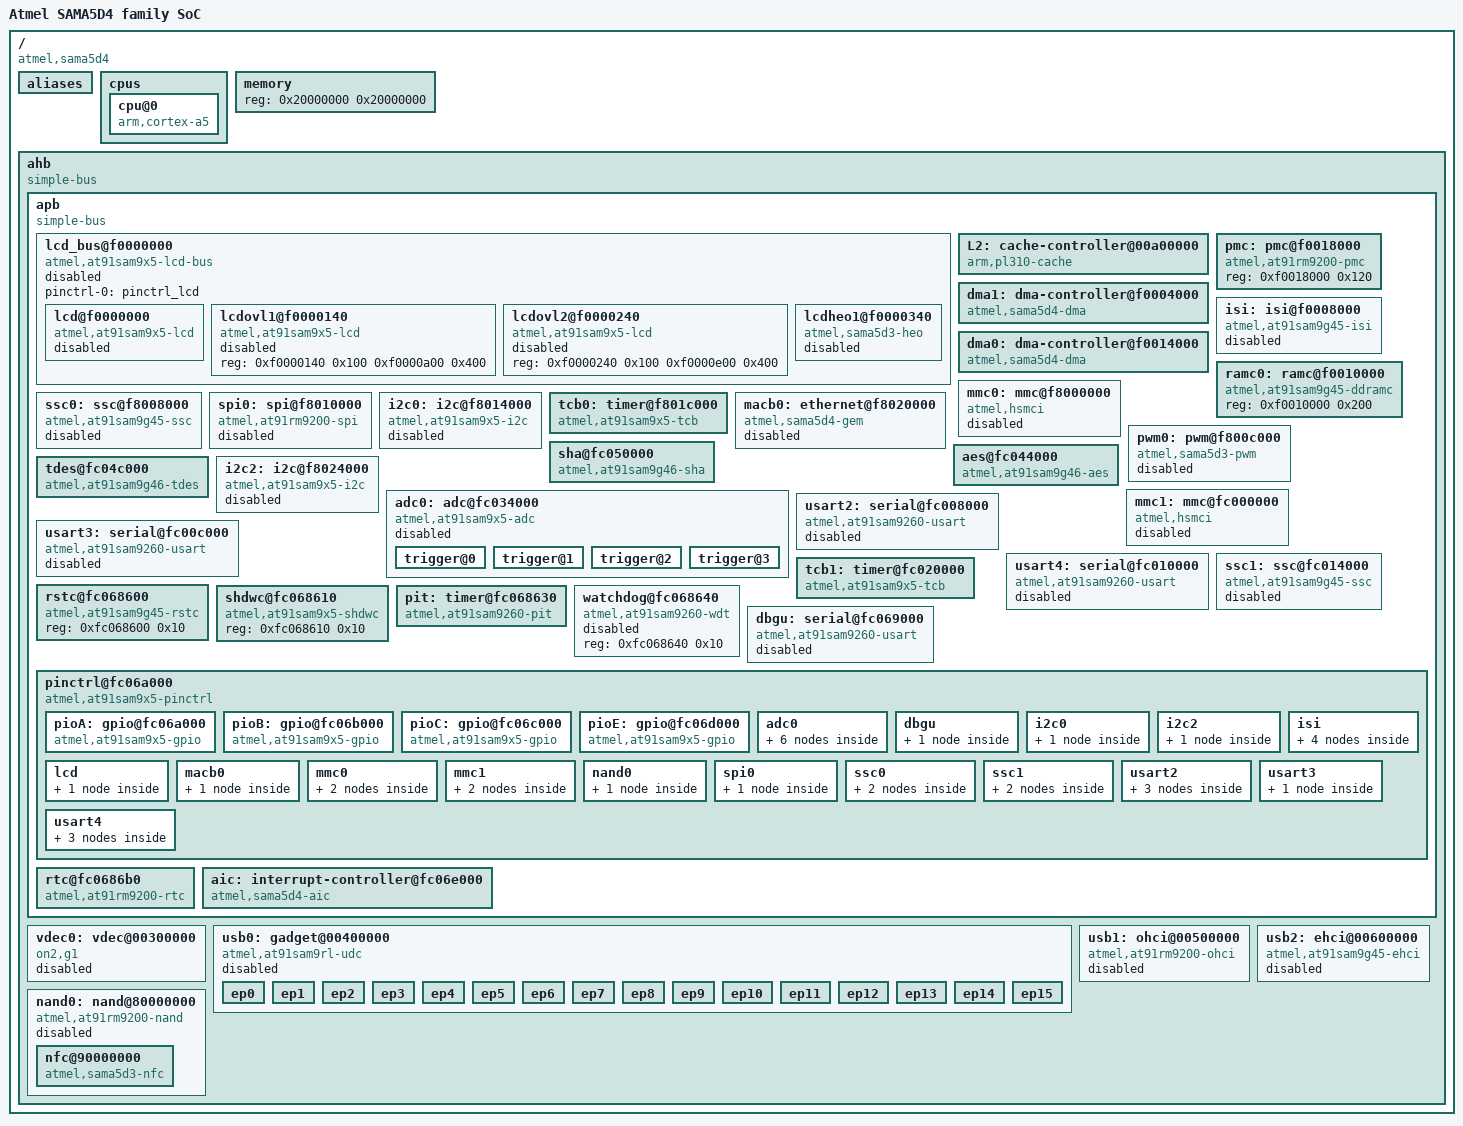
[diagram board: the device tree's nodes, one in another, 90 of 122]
/*
 * sama5d4.dtsi - Device Tree Include file for SAMA5D4 family SoC
 *
 *  Copyright (C) 2013 Atmel,
 *                2013 Nicolas Ferre <nicolas.ferre@atmel.com>
 *
 * Licensed under GPLv2 or later.
 */

#include "skeleton.dtsi"
#include <dt-bindings/dma/at91.h>
#include <dt-bindings/pinctrl/at91.h>
#include <dt-bindings/interrupt-controller/irq.h>
#include <dt-bindings/gpio/gpio.h>

/ {
	model = "Atmel SAMA5D4 family SoC";
	compatible = "atmel,sama5d4";
	interrupt-parent = <&aic>;

	aliases {
		serial0 = &usart3;
		serial1 = &usart4;
		serial2 = &usart2;
		gpio0 = &pioA;
		gpio1 = &pioB;
		gpio2 = &pioC;
		gpio4 = &pioE;
		tcb0 = &tcb0;
		tcb1 = &tcb1;
		i2c2 = &i2c2;
		ssc0 = &ssc0;
		ssc1 = &ssc1;
		pwm0 = &pwm0;
	};
	cpus {
		#address-cells = <1>;
		#size-cells = <0>;

		cpu@0 {
			device_type = "cpu";
			compatible = "arm,cortex-a5";
			reg = <0>;
			next-level-cache = <&L2>;
		};
	};

	memory {
		reg = <0x20000000 0x20000000>;
	};

	ahb {
		compatible = "simple-bus";
		#address-cells = <1>;
		#size-cells = <1>;
		ranges;

		apb {
			compatible = "simple-bus";
			#address-cells = <1>;
			#size-cells = <1>;
			ranges;

			lcd_bus@f0000000 {
				#address-cells = <1>;
				#size-cells = <1>;
				compatible = "atmel,at91sam9x5-lcd-bus", "simple-bus";
				ranges = <0xf0000000 0xf0000000 0x2000>;
				pinctrl-names = "default";
				pinctrl-0 = <&pinctrl_lcd>;
				status = "disabled";

				lcd@f0000000 {
					compatible = "atmel,at91sam9x5-lcd";
					reg = <0xf0000000 0x100
					       0xf0000600 0x400>;
					interrupts = <51 IRQ_TYPE_LEVEL_HIGH 3>;
					status = "disabled";
				};

				lcdovl1@f0000140 {
					compatible = "atmel,at91sam9x5-lcd";
					reg = <0xf0000140 0x100
					       0xf0000a00 0x400>;
					status = "disabled";
				};

				lcdovl2@f0000240 {
					compatible = "atmel,at91sam9x5-lcd";
					reg = <0xf0000240 0x100
					       0xf0000e00 0x400>;
					status = "disabled";
				};

				lcdheo1@f0000340 {
					compatible = "atmel,sama5d3-heo";
					reg = <0xf0000340 0x100
					       0xf0001200 0x400>;
					interrupts = <51 IRQ_TYPE_LEVEL_HIGH 3>;
					status = "disabled";
				};
			};

			L2: cache-controller@00a00000 {
				compatible = "arm,pl310-cache";
				reg = <0x00a00000 0x1000>;
				interrupts = <67 IRQ_TYPE_LEVEL_HIGH 0>;
				cache-unified;
				cache-level = <2>;
				/*arm,data-latency = <1 1 1>;*/
				/*arm,tag-latency = <1 1 1>;*/
			};

			pmc: pmc@f0018000 {
				compatible = "atmel,at91rm9200-pmc";
				reg = <0xf0018000 0x120>;
			};

			dma1: dma-controller@f0004000 {
				compatible = "atmel,sama5d4-dma";
				reg = <0xf0004000 0x200>;
				interrupts = <50 IRQ_TYPE_LEVEL_HIGH 0>;
				#dma-cells = <2>;
			};

			dma0: dma-controller@f0014000 {
				compatible = "atmel,sama5d4-dma";
				reg = <0xf0014000 0x200>;
				interrupts = <8 IRQ_TYPE_LEVEL_HIGH 0>;
				#dma-cells = <2>;
			};

			isi: isi@f0008000 {
				compatible = "atmel,at91sam9g45-isi";
				reg = <0xf0008000 0x4000>;
				interrupts = <52 IRQ_TYPE_LEVEL_HIGH 5>;
				pinctrl-names = "default";
				pinctrl-0 = <&pinctrl_isi &pinctrl_isi_mck &pinctrl_isi_power &pinctrl_isi_reset>;
				status = "disabled";
			};

			ramc0: ramc@f0010000 {
				compatible = "atmel,at91sam9g45-ddramc";
				reg = <0xf0010000 0x200>;
			};

			mmc0: mmc@f8000000 {
				compatible = "atmel,hsmci";
				reg = <0xf8000000 0x600>;
				interrupts = <35 IRQ_TYPE_LEVEL_HIGH 0>;
				dmas = <&dma1
					(AT91_XDMAC_DT_MEM_IF(0) | AT91_XDMAC_DT_PER_IF(1))
					(AT91_XDMAC_DT_PERID(0) | AT91_XDMAC_DT_DWIDTH(0x2))>;
				dma-names = "rxtx";
				pinctrl-names = "default";
				pinctrl-0 = <&pinctrl_mmc0_clk_cmd_dat0 &pinctrl_mmc0_dat1_3>;
				status = "disabled";
				#address-cells = <1>;
				#size-cells = <0>;
			};

			ssc0: ssc@f8008000 {
				compatible = "atmel,at91sam9g45-ssc";
				reg = <0xf8008000 0x4000>;
				interrupts = <48 IRQ_TYPE_LEVEL_HIGH 0>;
				pinctrl-names = "default";
				pinctrl-0 = <&pinctrl_ssc0_tx &pinctrl_ssc0_rx>;
				dmas = <&dma1
					(AT91_XDMAC_DT_MEM_IF(0) | AT91_XDMAC_DT_PER_IF(1))
					(AT91_XDMAC_DT_PERID(26) | AT91_XDMAC_DT_DWIDTH(0x1))>,
				       <&dma1
					(AT91_XDMAC_DT_MEM_IF(0) | AT91_XDMAC_DT_PER_IF(1))
					(AT91_XDMAC_DT_PERID(27) | AT91_XDMAC_DT_DWIDTH(0x1))>;
				dma-names = "tx", "rx";
				status = "disabled";
			};


			spi0: spi@f8010000 {
				#address-cells = <1>;
				#size-cells = <0>;
				compatible = "atmel,at91rm9200-spi";
				reg = <0xf8010000 0x100>;
				interrupts = <37 IRQ_TYPE_LEVEL_HIGH 3>;
				dmas = <&dma1
					(AT91_XDMAC_DT_MEM_IF(0) | AT91_XDMAC_DT_PER_IF(1))
					AT91_XDMAC_DT_PERID(10)>,
				       <&dma1
					(AT91_XDMAC_DT_MEM_IF(0) | AT91_XDMAC_DT_PER_IF(1))
					AT91_XDMAC_DT_PERID(11)>;
				dma-names = "tx", "rx";
				pinctrl-names = "default";
				pinctrl-0 = <&pinctrl_spi0>;
				status = "disabled";
			};

			i2c0: i2c@f8014000 {
				compatible = "atmel,at91sam9x5-i2c";
				reg = <0xf8014000 0x4000>;
				interrupts = <32 IRQ_TYPE_LEVEL_HIGH 6>;
				dmas = <&dma1
					(AT91_XDMAC_DT_MEM_IF(0) | AT91_XDMAC_DT_PER_IF(1))
					AT91_XDMAC_DT_PERID(2)>,
				       <&dma1
					(AT91_XDMAC_DT_MEM_IF(0) | AT91_XDMAC_DT_PER_IF(1))
					AT91_XDMAC_DT_PERID(3)>;
				dma-names = "tx", "rx";
				pinctrl-names = "default";
				pinctrl-0 = <&pinctrl_i2c0>;
				#address-cells = <1>;
				#size-cells = <0>;
				status = "disabled";
			};

			tcb0: timer@f801c000 {
				compatible = "atmel,at91sam9x5-tcb";
				reg = <0xf801c000 0x100>;
				interrupts = <40 IRQ_TYPE_LEVEL_HIGH 0>;
			};

			macb0: ethernet@f8020000 {
				compatible = "atmel,sama5d4-gem";
				reg = <0xf8020000 0x100>;
				interrupts = <54 IRQ_TYPE_LEVEL_HIGH 3>;
				pinctrl-names = "default";
				pinctrl-0 = <&pinctrl_macb0_rmii>;
				status = "disabled";
			};

			pwm0: pwm@f800c000 {
				compatible = "atmel,sama5d3-pwm";
				reg = <0xf800c000 0x300>;
				interrupts = <43 IRQ_TYPE_LEVEL_HIGH 4>;
				#pwm-cells = <3>;
				status = "disabled";
			};

			sha@fc050000 {
				compatible = "atmel,at91sam9g46-sha";
				reg = <0xfc050000 0x100>;
				interrupts = <15 IRQ_TYPE_LEVEL_HIGH 0>;
				dmas = <&dma0 (AT91_XDMAC_DT_MEM_IF(0) | AT91_XDMAC_DT_PER_IF(1))
					AT91_XDMAC_DT_PERID(44)>;
				dma-names = "tx";
			};

			aes@fc044000 {
				compatible = "atmel,at91sam9g46-aes";
				reg = <0xfc044000 0x100>;
				interrupts = <12 IRQ_TYPE_LEVEL_HIGH 0>;
				dmas = <&dma0 (AT91_XDMAC_DT_MEM_IF(0) | AT91_XDMAC_DT_PER_IF(1))
					AT91_XDMAC_DT_PERID(41)>,
					<&dma0 (AT91_XDMAC_DT_MEM_IF(0) | AT91_XDMAC_DT_PER_IF(1))
					AT91_XDMAC_DT_PERID(40)>;
				dma-names = "tx", "rx";
			};

			tdes@fc04c000 {
				compatible = "atmel,at91sam9g46-tdes";
				reg = <0xfc04c000 0x100>;
				interrupts = <14 IRQ_TYPE_LEVEL_HIGH 0>;
				dmas = <&dma0 (AT91_XDMAC_DT_MEM_IF(0) | AT91_XDMAC_DT_PER_IF(1))
					AT91_XDMAC_DT_PERID(42)>,
					<&dma0 (AT91_XDMAC_DT_MEM_IF(0) | AT91_XDMAC_DT_PER_IF(1))
					AT91_XDMAC_DT_PERID(43)>;
				dma-names = "tx", "rx";
			};

			i2c2: i2c@f8024000 {
				compatible = "atmel,at91sam9x5-i2c";
				reg = <0xf8024000 0x4000>;
				interrupts = <34 4 6>;
				dmas = <&dma1
					(AT91_XDMAC_DT_MEM_IF(0) | AT91_XDMAC_DT_PER_IF(1))
					AT91_XDMAC_DT_PERID(6)>,
				       <&dma1
					(AT91_XDMAC_DT_MEM_IF(0) | AT91_XDMAC_DT_PER_IF(1))
					AT91_XDMAC_DT_PERID(7)>;
				dma-names = "tx", "rx";
				pinctrl-names = "default";
				pinctrl-0 = <&pinctrl_i2c2>;
				#address-cells = <1>;
				#size-cells = <0>;
				status = "disabled";
			};

			adc0: adc@fc034000 {
				compatible = "atmel,at91sam9x5-adc";
				reg = <0xfc034000 0x100>;
				interrupts = <44 IRQ_TYPE_LEVEL_HIGH 5>;
				pinctrl-names = "default";
				pinctrl-0 = <
					/* external trigger is conflict with USBA_VBUS */
					&pinctrl_adc0_ad0
					&pinctrl_adc0_ad1
					&pinctrl_adc0_ad2
					&pinctrl_adc0_ad3
					&pinctrl_adc0_ad4
					>;
				atmel,adc-channels-used = <0x01f>;
				atmel,adc-startup-time = <40>;
				atmel,adc-use-external;
				atmel,adc-vref = <3000>;
				atmel,adc-res = <8 10>;
				atmel,adc-sample-hold-time = <11>;
				atmel,adc-res-names = "lowres", "highres";
				atmel,adc-clock-rate = <1000000>;
				atmel,adc-ts-pressure-threshold = <10000>;
				status = "disabled";

				trigger@0 {
					trigger-name = "external-rising";
					trigger-value = <0x1>;
					trigger-external;
				};
				trigger@1 {
					trigger-name = "external-falling";
					trigger-value = <0x2>;
					trigger-external;
				};
				trigger@2 {
					trigger-name = "external-any";
					trigger-value = <0x3>;
					trigger-external;
				};
				trigger@3 {
					trigger-name = "continuous";
					trigger-value = <0x6>;
				};
			};

			mmc1: mmc@fc000000 {
				compatible = "atmel,hsmci";
				reg = <0xfc000000 0x600>;
				interrupts = <36 IRQ_TYPE_LEVEL_HIGH 0>;
				dmas = <&dma1
					(AT91_XDMAC_DT_MEM_IF(0) | AT91_XDMAC_DT_PER_IF(1))
					(AT91_XDMAC_DT_PERID(1) | AT91_XDMAC_DT_DWIDTH(0x2))>;
				dma-names = "rxtx";
				pinctrl-names = "default";
				pinctrl-0 = <&pinctrl_mmc1_clk_cmd_dat0 &pinctrl_mmc1_dat1_3>;
				status = "disabled";
				#address-cells = <1>;
				#size-cells = <0>;
			};

			usart2: serial@fc008000 {
				compatible = "atmel,at91sam9260-usart";
				reg = <0xfc008000 0x100>;
				interrupts = <29 IRQ_TYPE_LEVEL_HIGH 5>;
				dmas = <&dma1
					(AT91_XDMAC_DT_MEM_IF(0) | AT91_XDMAC_DT_PER_IF(1))
					(AT91_XDMAC_DT_PERID(16) | AT91_XDMAC_DT_DWIDTH(0x0))>,
				       <&dma1
					(AT91_XDMAC_DT_MEM_IF(0) | AT91_XDMAC_DT_PER_IF(1))
					(AT91_XDMAC_DT_PERID(17) | AT91_XDMAC_DT_DWIDTH(0x0))>;
				dma-names = "tx", "rx";
				pinctrl-names = "default";
				pinctrl-0 = <&pinctrl_usart2 &pinctrl_usart2_rts &pinctrl_usart2_cts>;
				status = "disabled";
			};

			usart3: serial@fc00c000 {
				compatible = "atmel,at91sam9260-usart";
				reg = <0xfc00c000 0x100>;
				interrupts = <30 IRQ_TYPE_LEVEL_HIGH 5>;
				dmas = <&dma1
					(AT91_XDMAC_DT_MEM_IF(0) | AT91_XDMAC_DT_PER_IF(1))
					(AT91_XDMAC_DT_PERID(18) | AT91_XDMAC_DT_DWIDTH(0x0))>,
				       <&dma1
					(AT91_XDMAC_DT_MEM_IF(0) | AT91_XDMAC_DT_PER_IF(1))
					(AT91_XDMAC_DT_PERID(19) | AT91_XDMAC_DT_DWIDTH(0x0))>;
				dma-names = "tx", "rx";
				pinctrl-names = "default";
				pinctrl-0 = <&pinctrl_usart3>;
				status = "disabled";
			};

			usart4: serial@fc010000 {
				compatible = "atmel,at91sam9260-usart";
				reg = <0xfc010000 0x100>;
				interrupts = <31 IRQ_TYPE_LEVEL_HIGH 5>;
				dmas = <&dma1
					(AT91_XDMAC_DT_MEM_IF(0) | AT91_XDMAC_DT_PER_IF(1))
					(AT91_XDMAC_DT_PERID(20) | AT91_XDMAC_DT_DWIDTH(0x0))>,
				       <&dma1
					(AT91_XDMAC_DT_MEM_IF(0) | AT91_XDMAC_DT_PER_IF(1))
					(AT91_XDMAC_DT_PERID(21) | AT91_XDMAC_DT_DWIDTH(0x0))>;
				dma-names = "tx", "rx";
				pinctrl-names = "default";
				pinctrl-0 = <&pinctrl_usart4>;
				status = "disabled";
			};

			ssc1: ssc@fc014000 {
				compatible = "atmel,at91sam9g45-ssc";
				reg = <0xfc014000 0x4000>;
				interrupts = <49 IRQ_TYPE_LEVEL_HIGH 0>;
				pinctrl-names = "default";
				pinctrl-0 = <&pinctrl_ssc1_tx &pinctrl_ssc1_rx>;
				dmas = <&dma1 AT91_XDMAC_DT_PERID(28)>,
				       <&dma1 AT91_XDMAC_DT_PERID(29)>;
				dma-names = "tx", "rx";
				status = "disabled";
			};

			tcb1: timer@fc020000 {
				compatible = "atmel,at91sam9x5-tcb";
				reg = <0xfc020000 0x100>;
				interrupts = <41 IRQ_TYPE_LEVEL_HIGH 0>;
			};

			rstc@fc068600 {
				compatible = "atmel,at91sam9g45-rstc";
				reg = <0xfc068600 0x10>;
			};

			shdwc@fc068610 {
				compatible = "atmel,at91sam9x5-shdwc";
				reg = <0xfc068610 0x10>;
			};

			pit: timer@fc068630 {
				compatible = "atmel,at91sam9260-pit";
				reg = <0xfc068630 0xf>;
				interrupts = <3 IRQ_TYPE_LEVEL_HIGH 5>;
			};

			watchdog@fc068640 {
				compatible = "atmel,at91sam9260-wdt";
				reg = <0xfc068640 0x10>;
				status = "disabled";
			};

			dbgu: serial@fc069000 {
				compatible = "atmel,at91sam9260-usart";
				reg = <0xfc069000 0x200>;
				interrupts = <2 IRQ_TYPE_LEVEL_HIGH 7>;
				pinctrl-names = "default";
				pinctrl-0 = <&pinctrl_dbgu>;
				status = "disabled";
			};


			pinctrl@fc06a000 {
				#address-cells = <1>;
				#size-cells = <1>;
				compatible = "atmel,at91sam9x5-pinctrl", "atmel,at91rm9200-pinctrl", "simple-bus";
				ranges = <0xfc06a000 0xfc06a000 0x4000>;
				/* WARNING: revisit as pin spec has changed */
				atmel,mux-mask = <
					/*   A          B          C  */
					0xffffffff 0x3ffcfe7c 0x1c010101	/* pioA */
					0x7fffffff 0xfffccc3a 0x3f00cc3a	/* pioB */
					0xffffffff 0x3ff83fff 0xff00ffff	/* pioC */
					0x00000000 0x00000000 0x00000000	/* pioD */
					0xffffffff 0x7fffffff 0x76fff1bf	/* pioE */
					>;

				pioA: gpio@fc06a000 {
					compatible = "atmel,at91sam9x5-gpio", "atmel,at91rm9200-gpio";
					reg = <0xfc06a000 0x100>;
					interrupts = <23 IRQ_TYPE_LEVEL_HIGH 1>;
					#gpio-cells = <2>;
					gpio-controller;
					interrupt-controller;
					#interrupt-cells = <2>;
				};

				pioB: gpio@fc06b000 {
					compatible = "atmel,at91sam9x5-gpio", "atmel,at91rm9200-gpio";
					reg = <0xfc06b000 0x100>;
					interrupts = <24 IRQ_TYPE_LEVEL_HIGH 1>;
					#gpio-cells = <2>;
					gpio-controller;
					interrupt-controller;
					#interrupt-cells = <2>;
				};

				pioC: gpio@fc06c000 {
					compatible = "atmel,at91sam9x5-gpio", "atmel,at91rm9200-gpio";
					reg = <0xfc06c000 0x100>;
					interrupts = <25 IRQ_TYPE_LEVEL_HIGH 1>;
					#gpio-cells = <2>;
					gpio-controller;
					interrupt-controller;
					#interrupt-cells = <2>;
				};

				pioE: gpio@fc06d000 {
					compatible = "atmel,at91sam9x5-gpio", "atmel,at91rm9200-gpio";
					reg = <0xfc06d000 0x100>;
					interrupts = <26 IRQ_TYPE_LEVEL_HIGH 1>;
					#gpio-cells = <2>;
					gpio-controller;
					interrupt-controller;
					#interrupt-cells = <2>;
				};

				/* pinctrl pin settings */
				adc0 {
					pinctrl_adc0_adtrg: adc0_adtrg {
						atmel,pins =
							<AT91_PIOE 31 AT91_PERIPH_A AT91_PINCTRL_NONE>;	/* conflicts with USBA_VBUS */
					};
					pinctrl_adc0_ad0: adc0_ad0 {
						atmel,pins =
							<AT91_PIOC 27 AT91_PERIPH_A AT91_PINCTRL_NONE>;
					};
					pinctrl_adc0_ad1: adc0_ad1 {
						atmel,pins =
							<AT91_PIOC 28 AT91_PERIPH_A AT91_PINCTRL_NONE>;
					};
					pinctrl_adc0_ad2: adc0_ad2 {
						atmel,pins =
							<AT91_PIOC 29 AT91_PERIPH_A AT91_PINCTRL_NONE>;
					};
					pinctrl_adc0_ad3: adc0_ad3 {
						atmel,pins =
							<AT91_PIOC 30 AT91_PERIPH_A AT91_PINCTRL_NONE>;
					};
					pinctrl_adc0_ad4: adc0_ad4 {
						atmel,pins =
							<AT91_PIOC 31 AT91_PERIPH_A AT91_PINCTRL_NONE>;
					};
				};

				dbgu {
					pinctrl_dbgu: dbgu-0 {
						atmel,pins =
							<AT91_PIOB 24 AT91_PERIPH_A AT91_PINCTRL_NONE>,     /* conflicts with D14 and TDI */
							<AT91_PIOB 25 AT91_PERIPH_A AT91_PINCTRL_PULL_UP>;  /* conflicts with D15 and TDO */
					};
				};

				i2c0 {
					pinctrl_i2c0: i2c0-0 {
						atmel,pins =
							<AT91_PIOA 30 AT91_PERIPH_A AT91_PINCTRL_NONE
							 AT91_PIOA 31 AT91_PERIPH_A AT91_PINCTRL_NONE>;
					};
				};

				i2c2 {
					pinctrl_i2c2: i2c2-0 {
						atmel,pins =
							<AT91_PIOB 29 AT91_PERIPH_A AT91_PINCTRL_NONE	/* TWD2, conflicts with RD0 and PWML1 */
							 AT91_PIOB 30 AT91_PERIPH_A AT91_PINCTRL_NONE>; /* TWCK2, conflicts with RF0 */
					};
				};

				isi {
					pinctrl_isi: isi-0 {
						atmel,pins =
							<AT91_PIOC 19 AT91_PERIPH_A AT91_PINCTRL_NONE	/* ISI_D0 */
							 AT91_PIOC 20 AT91_PERIPH_A AT91_PINCTRL_NONE	/* ISI_D1 */
							 AT91_PIOC 21 AT91_PERIPH_A AT91_PINCTRL_NONE	/* ISI_D2 */
							 AT91_PIOC 22 AT91_PERIPH_A AT91_PINCTRL_NONE	/* ISI_D3 */
							 AT91_PIOC 23 AT91_PERIPH_A AT91_PINCTRL_NONE	/* ISI_D4 */
							 AT91_PIOC 24 AT91_PERIPH_A AT91_PINCTRL_NONE	/* ISI_D5 */
							 AT91_PIOC 25 AT91_PERIPH_A AT91_PINCTRL_NONE	/* ISI_D6 */
							 AT91_PIOC 26 AT91_PERIPH_A AT91_PINCTRL_NONE	/* ISI_D7 */
							 AT91_PIOB  1 AT91_PERIPH_C AT91_PINCTRL_NONE	/* ISI_PCK, conflict with G0_RXCK */
							 AT91_PIOB  3 AT91_PERIPH_C AT91_PINCTRL_NONE	/* ISI_VSYNC */
							 AT91_PIOB  4 AT91_PERIPH_C AT91_PINCTRL_NONE>;	/* ISI_HSYNC */
					};
					pinctrl_isi_mck: isi_mck-0 {
						atmel,pins =
							<AT91_PIOC 4 AT91_PERIPH_C AT91_PINCTRL_NONE>;	/* ISI_MCK(PCK1), conflict with MCI0_CK, SPI0_NPCS1 */
					};
					pinctrl_isi_reset: isi_reset-0 {
						atmel,pins =
							<AT91_PIOB 11 AT91_PERIPH_GPIO AT91_PINCTRL_NONE>;   /* PB11 gpio ISI_RST */
					};

					pinctrl_isi_power: isi_power-0 {
						atmel,pins =
							<AT91_PIOB 5 AT91_PERIPH_GPIO AT91_PINCTRL_NONE>; /* PB5 gpio ISI_PWD */
					};
				};

				lcd {
					pinctrl_lcd: lcd-0 {
						atmel,pins = <
							/* AT91_PIOA 0 AT91_PERIPH_A AT91_PINCTRL_NONE */ /* LCDDAT0, conflicts with TMS */
							 AT91_PIOA 1 AT91_PERIPH_A AT91_PINCTRL_NONE /* LCDDAT1 */
							 AT91_PIOA 2 AT91_PERIPH_A AT91_PINCTRL_NONE /* LCDDAT2 */
							 AT91_PIOA 3 AT91_PERIPH_A AT91_PINCTRL_NONE /* LCDDAT3 */
							 AT91_PIOA 4 AT91_PERIPH_A AT91_PINCTRL_NONE /* LCDDAT4 */
							 AT91_PIOA 5 AT91_PERIPH_A AT91_PINCTRL_NONE /* LCDDAT5 */
							 AT91_PIOA 6 AT91_PERIPH_A AT91_PINCTRL_NONE /* LCDDAT6 */
							 AT91_PIOA 7 AT91_PERIPH_A AT91_PINCTRL_NONE /* LCDDAT7 */
							/* AT91_PIOA 8 AT91_PERIPH_A AT91_PINCTRL_NONE */ /* LCDDAT8, conflicts with TCK */
							 AT91_PIOA 9 AT91_PERIPH_A AT91_PINCTRL_NONE /* LCDDAT9 */
							 AT91_PIOA 10 AT91_PERIPH_A AT91_PINCTRL_NONE /* LCDDAT10 */
							 AT91_PIOA 11 AT91_PERIPH_A AT91_PINCTRL_NONE /* LCDDAT11 */
							 AT91_PIOA 12 AT91_PERIPH_A AT91_PINCTRL_NONE /* LCDDAT12 */
							 AT91_PIOA 13 AT91_PERIPH_A AT91_PINCTRL_NONE /* LCDDAT13 */
							 AT91_PIOA 14 AT91_PERIPH_A AT91_PINCTRL_NONE /* LCDDAT14 */
							 AT91_PIOA 15 AT91_PERIPH_A AT91_PINCTRL_NONE /* LCDDAT15 */
							/* AT91_PIOA 16 AT91_PERIPH_A AT91_PINCTRL_NONE */ /* LCDDAT16, conflicts with NTRST */
							 AT91_PIOA 17 AT91_PERIPH_A AT91_PINCTRL_NONE /* LCDDAT17 */
							 AT91_PIOA 18 AT91_PERIPH_A AT91_PINCTRL_NONE /* LCDDAT18 */
							 AT91_PIOA 19 AT91_PERIPH_A AT91_PINCTRL_NONE /* LCDDAT19 */
							 AT91_PIOA 20 AT91_PERIPH_A AT91_PINCTRL_NONE /* LCDDAT20 */
							 AT91_PIOA 21 AT91_PERIPH_A AT91_PINCTRL_NONE /* LCDDAT21 */
							 AT91_PIOA 22 AT91_PERIPH_A AT91_PINCTRL_NONE /* LCDDAT22 */
							 AT91_PIOA 23 AT91_PERIPH_A AT91_PINCTRL_NONE /* LCDDAT23 */
							 AT91_PIOA 29 AT91_PERIPH_A AT91_PINCTRL_NONE /* LCDDEN, conflicts with PWML1 */
							 AT91_PIOA 27 AT91_PERIPH_A AT91_PINCTRL_NONE /* LCDHSYNC, conflicts with PWML0 and SPI1_NPCS2 */
							 AT91_PIOA 28 AT91_PERIPH_A AT91_PINCTRL_NONE /* LCDPCK, conflicts with PWMH1 and SPI1_NPCS3 */
							 AT91_PIOA 24 AT91_PERIPH_A AT91_PINCTRL_NONE /* LCDPWM, conflicts with PCK0 */
							 AT91_PIOA 26 AT91_PERIPH_A AT91_PINCTRL_NONE /* LCDVSYNC, conflicts with PWMH0 and SPI1_NPCS1 */
							>;
					};
				};

				macb0 {
					pinctrl_macb0_rmii: macb0_rmii-0 {
						atmel,pins =
							<AT91_PIOB 12 AT91_PERIPH_A AT91_PINCTRL_NONE	/* G0_TX0 */
							 AT91_PIOB 13 AT91_PERIPH_A AT91_PINCTRL_NONE	/* G0_TX1 */
							 AT91_PIOB  8 AT91_PERIPH_A AT91_PINCTRL_NONE	/* G0_RX0 */
							 AT91_PIOB  9 AT91_PERIPH_A AT91_PINCTRL_NONE	/* G0_RX1 */
							 AT91_PIOB  6 AT91_PERIPH_A AT91_PINCTRL_NONE	/* G0_RXDV */
							 AT91_PIOB  7 AT91_PERIPH_A AT91_PINCTRL_NONE	/* G0_RXER */
							 AT91_PIOB  2 AT91_PERIPH_A AT91_PINCTRL_NONE	/* G0_TXEN */
							 AT91_PIOB  0 AT91_PERIPH_A AT91_PINCTRL_NONE	/* G0_TXCK */
							 AT91_PIOB 16 AT91_PERIPH_A AT91_PINCTRL_NONE	/* G0_MDC */
							 AT91_PIOB 17 AT91_PERIPH_A AT91_PINCTRL_NONE	/* G0_MDIO */
							>;
					};
				};

				mmc0 {
					pinctrl_mmc0_clk_cmd_dat0: mmc0_clk_cmd_dat0 {
						atmel,pins =
							<AT91_PIOC 4 AT91_PERIPH_B AT91_PINCTRL_NONE	/* MCI0_CK, conflict with PCK1(ISI_MCK) */
							 AT91_PIOC 5 AT91_PERIPH_B AT91_PINCTRL_PULL_UP	/* MCI0_CDB, conflict with NAND_D0 */
							 AT91_PIOC 6 AT91_PERIPH_B AT91_PINCTRL_PULL_UP	/* MCI0_DB0, conflict with NAND_D1 */
							>;
					};
					pinctrl_mmc0_dat1_3: mmc0_dat1_3 {
						atmel,pins =
							<AT91_PIOC 7 AT91_PERIPH_B AT91_PINCTRL_PULL_UP	/* MCI0_DB1, conflict with NAND_D2 */
							 AT91_PIOC 8 AT91_PERIPH_B AT91_PINCTRL_PULL_UP	/* MCI0_DB2, conflict with NAND_D3 */
							 AT91_PIOC 9 AT91_PERIPH_B AT91_PINCTRL_PULL_UP	/* MCI0_DB3, conflict with NAND_D4 */
							>;
					};
				};

				mmc1 {
					pinctrl_mmc1_clk_cmd_dat0: mmc1_clk_cmd_dat0 {
						atmel,pins =
							<AT91_PIOE 18 AT91_PERIPH_C AT91_PINCTRL_NONE		/* MCI1_CK */
							 AT91_PIOE 19 AT91_PERIPH_C AT91_PINCTRL_PULL_UP	/* MCI1_CDA */
							 AT91_PIOE 20 AT91_PERIPH_C AT91_PINCTRL_PULL_UP	/* MCI1_DA0 */
							>;
					};
					pinctrl_mmc1_dat1_3: mmc1_dat1_3 {
						atmel,pins =
							<AT91_PIOE 21 AT91_PERIPH_C AT91_PINCTRL_PULL_UP	/* MCI1_DA1 */
							 AT91_PIOE 22 AT91_PERIPH_C AT91_PINCTRL_PULL_UP	/* MCI1_DA2 */
							 AT91_PIOE 23 AT91_PERIPH_C AT91_PINCTRL_PULL_UP	/* MCI1_DA3 */
							>;
					};
				};

				nand0 {
					pinctrl_nand: nand-0 {
						atmel,pins =
							<AT91_PIOC 13 AT91_PERIPH_A AT91_PINCTRL_NONE	/* PC13 periph A Read Enable */
							 AT91_PIOC 14 AT91_PERIPH_A AT91_PINCTRL_NONE	/* PC14 periph A Write Enable */

							 AT91_PIOC 17 AT91_PERIPH_A AT91_PINCTRL_PULL_UP	/* PC17 ALE */
							 AT91_PIOC 18 AT91_PERIPH_A AT91_PINCTRL_PULL_UP	/* PC18 CLE */

							 AT91_PIOC 15 AT91_PERIPH_A AT91_PINCTRL_PULL_UP	/* PC15 NCS3/Chip Enable */
							 AT91_PIOC 16 AT91_PERIPH_A AT91_PINCTRL_PULL_UP	/* PC16 NANDRDY */
							 AT91_PIOC 5 AT91_PERIPH_A AT91_PINCTRL_NONE	/* PC5 Data bit 0 */
							 AT91_PIOC 6 AT91_PERIPH_A AT91_PINCTRL_NONE	/* PC6 Data bit 1 */
							 AT91_PIOC 7 AT91_PERIPH_A AT91_PINCTRL_NONE	/* PC7 Data bit 2 */
							 AT91_PIOC 8 AT91_PERIPH_A AT91_PINCTRL_NONE	/* PC8 Data bit 3 */
							 AT91_PIOC 9 AT91_PERIPH_A AT91_PINCTRL_NONE	/* PC9 Data bit 4 */
							 AT91_PIOC 10 AT91_PERIPH_A AT91_PINCTRL_NONE	/* PC10 Data bit 5 */
							 AT91_PIOC 11 AT91_PERIPH_A AT91_PINCTRL_NONE	/* PC11 periph A Data bit 6 */
							 AT91_PIOC 12 AT91_PERIPH_A AT91_PINCTRL_NONE>;	/* PC12 periph A Data bit 7 */
					};
				};
				spi0 {
					pinctrl_spi0: spi0-0 {
						atmel,pins =
							<AT91_PIOC 0 AT91_PERIPH_A AT91_PINCTRL_NONE	/* SPI0_MISO */
							 AT91_PIOC 1 AT91_PERIPH_A AT91_PINCTRL_NONE	/* SPI0_MOSI */
							 AT91_PIOC 2 AT91_PERIPH_A AT91_PINCTRL_NONE	/* SPI0_SPCK */
							>;
					};
				};

				ssc0 {
					pinctrl_ssc0_tx: ssc0_tx {
						atmel,pins =
							<AT91_PIOB 27 AT91_PERIPH_B AT91_PINCTRL_NONE	/* PB27 periph B TK0 */
							 AT91_PIOB 31 AT91_PERIPH_B AT91_PINCTRL_NONE	/* PB31 periph B TF0 */
							 AT91_PIOB 28 AT91_PERIPH_B AT91_PINCTRL_NONE>;	/* PB28 periph B TD0 */
					};

					pinctrl_ssc0_rx: ssc0_rx {
						atmel,pins =
							<AT91_PIOB 26 AT91_PERIPH_B AT91_PINCTRL_NONE	/* PB26 periph B RK0 */
							 AT91_PIOB 30 AT91_PERIPH_B AT91_PINCTRL_NONE	/* PB30 periph B RF0 */
							 AT91_PIOB 29 AT91_PERIPH_B AT91_PINCTRL_NONE>;	/* PB29 periph B RD0 */
					};
				};

				ssc1 {
					pinctrl_ssc1_tx: ssc1_tx {
						atmel,pins =
							<AT91_PIOC 19 AT91_PERIPH_B AT91_PINCTRL_NONE	/* PC19 periph B TK1 */
							 AT91_PIOC 20 AT91_PERIPH_B AT91_PINCTRL_NONE	/* PC20 periph B TF1 */
							 AT91_PIOC 21 AT91_PERIPH_B AT91_PINCTRL_NONE>;	/* PC21 periph B TD1 */
					};

					pinctrl_ssc1_rx: ssc1_rx {
						atmel,pins =
							<AT91_PIOC 24 AT91_PERIPH_B AT91_PINCTRL_NONE	/* PC7 periph B RK1 */
							 AT91_PIOC 22 AT91_PERIPH_B AT91_PINCTRL_NONE	/* PC10 periph B RF1 */
							 AT91_PIOC 23 AT91_PERIPH_B AT91_PINCTRL_NONE>;	/* PC11 periph B RD1 */
					};
				};

				usart2 {
					pinctrl_usart2: usart2-0 {
						atmel,pins =
							<AT91_PIOB 4 AT91_PERIPH_B AT91_PINCTRL_NONE		/* RXD - conflicts with G0_CRS, ISI_HSYNC */
							 AT91_PIOB 5 AT91_PERIPH_B AT91_PINCTRL_PULL_UP		/* TXD - conflicts with G0_COL, PCK2 */
							>;
					};
					pinctrl_usart2_rts: usart2_rts-0 {
						atmel,pins = <AT91_PIOB 11 AT91_PERIPH_B AT91_PINCTRL_NONE>;	/* conflicts with G0_RX3, PWMH1 */
					};
					pinctrl_usart2_cts: usart2_cts-0 {
						atmel,pins = <AT91_PIOB 3 AT91_PERIPH_B AT91_PINCTRL_NONE>;	/* conflicts with G0_TXER, ISI_VSYNC */
					};
				};
				usart3 {
					pinctrl_usart3: usart3-0 {
						atmel,pins =
							<AT91_PIOE 16 AT91_PERIPH_B AT91_PINCTRL_NONE		/* RXD */
							 AT91_PIOE 17 AT91_PERIPH_B AT91_PINCTRL_PULL_UP	/* TXD */
							>;
					};
				};
				usart4 {
					pinctrl_usart4: usart4-0 {
						atmel,pins =
							<AT91_PIOE 26 AT91_PERIPH_B AT91_PINCTRL_NONE		/* RXD */
							 AT91_PIOE 27 AT91_PERIPH_B AT91_PINCTRL_PULL_UP	/* TXD */
							>;
					};
					pinctrl_usart4_rts: usart4_rts-0 {
						atmel,pins = <AT91_PIOE 28 AT91_PERIPH_B AT91_PINCTRL_NONE>;	/* conflicts with NWAIT, A19 */
					};
					pinctrl_usart4_cts: usart4_cts-0 {
						atmel,pins = <AT91_PIOE 0 AT91_PERIPH_C AT91_PINCTRL_NONE>;	/* conflicts with A0/NBS0, MCI0_CDB */
					};
				};
			};

			rtc@fc0686b0 {
				compatible = "atmel,at91rm9200-rtc";
				reg = <0xfc0686b0 0x30>;
				interrupts = <1 IRQ_TYPE_LEVEL_HIGH 7>;
			};

			aic: interrupt-controller@fc06e000 {
				#interrupt-cells = <3>;
				compatible = "atmel,sama5d4-aic";
				interrupt-controller;
				reg = <0xfc06e000 0x200>;
				atmel,external-irqs = <56>;
			};
		};

		vdec0: vdec@00300000 {
			compatible = "on2,g1";
			reg = <0x00300000 0x1000>;
			interrupts = <19 IRQ_TYPE_LEVEL_HIGH 4>;
			status = "disabled";
		};

		usb0: gadget@00400000 {
			#address-cells = <1>;
			#size-cells = <0>;
			compatible = "atmel,at91sam9rl-udc";
			reg = <0x00400000 0x100000
			       0xfc02c000 0x4000>;
			interrupts = <47 IRQ_TYPE_LEVEL_HIGH 2>;
			status = "disabled";

			ep0 {
				reg = <0>;
				atmel,fifo-size = <64>;
				atmel,nb-banks = <1>;
			};

			ep1 {
				reg = <1>;
				atmel,fifo-size = <1024>;
				atmel,nb-banks = <3>;
				atmel,can-dma;
				atmel,can-isoc;
			};

			ep2 {
				reg = <2>;
				atmel,fifo-size = <1024>;
				atmel,nb-banks = <3>;
				atmel,can-dma;
				atmel,can-isoc;
			};

			ep3 {
				reg = <3>;
				atmel,fifo-size = <1024>;
				atmel,nb-banks = <2>;
				atmel,can-dma;
				atmel,can-isoc;
			};

			ep4 {
				reg = <4>;
				atmel,fifo-size = <1024>;
				atmel,nb-banks = <2>;
				atmel,can-dma;
				atmel,can-isoc;
			};

			ep5 {
				reg = <5>;
				atmel,fifo-size = <1024>;
				atmel,nb-banks = <2>;
				atmel,can-dma;
				atmel,can-isoc;
			};

			ep6 {
				reg = <6>;
				atmel,fifo-size = <1024>;
				atmel,nb-banks = <2>;
				atmel,can-dma;
				atmel,can-isoc;
			};

			ep7 {
				reg = <7>;
				atmel,fifo-size = <1024>;
				atmel,nb-banks = <2>;
				atmel,can-dma;
				atmel,can-isoc;
			};

			ep8 {
				reg = <8>;
				atmel,fifo-size = <1024>;
				atmel,nb-banks = <2>;
				atmel,can-isoc;
			};

			ep9 {
				reg = <9>;
				atmel,fifo-size = <1024>;
				atmel,nb-banks = <2>;
				atmel,can-isoc;
			};

			ep10 {
				reg = <10>;
				atmel,fifo-size = <1024>;
				atmel,nb-banks = <2>;
				atmel,can-isoc;
			};

			ep11 {
				reg = <11>;
				atmel,fifo-size = <1024>;
				atmel,nb-banks = <2>;
				atmel,can-isoc;
			};

			ep12 {
				reg = <12>;
				atmel,fifo-size = <1024>;
				atmel,nb-banks = <2>;
				atmel,can-isoc;
			};

			ep13 {
				reg = <13>;
				atmel,fifo-size = <1024>;
				atmel,nb-banks = <2>;
				atmel,can-isoc;
			};

			ep14 {
				reg = <14>;
				atmel,fifo-size = <1024>;
				atmel,nb-banks = <2>;
				atmel,can-isoc;
			};

			ep15 {
				reg = <15>;
				atmel,fifo-size = <1024>;
				atmel,nb-banks = <2>;
				atmel,can-isoc;
			};
		};

		usb1: ohci@00500000 {
			compatible = "atmel,at91rm9200-ohci", "usb-ohci";
			reg = <0x00500000 0x100000>;
			interrupts = <46 IRQ_TYPE_LEVEL_HIGH 2>;
			status = "disabled";
		};

		usb2: ehci@00600000 {
			compatible = "atmel,at91sam9g45-ehci", "usb-ehci";
			reg = <0x00600000 0x100000>;
			interrupts = <46 IRQ_TYPE_LEVEL_HIGH 2>;
			status = "disabled";
		};

		nand0: nand@80000000 {
			compatible = "atmel,at91rm9200-nand";
			#address-cells = <1>;
			#size-cells = <1>;
			ranges;
			reg = <	0x80000000 0x08000000	/* EBI CS3 */
				0xfc05c070 0x00000490	/* SMC PMECC regs */
				0xfc05c500 0x00000100	/* SMC PMECC Error Location regs */
				>;
			interrupts = <22 IRQ_TYPE_LEVEL_HIGH 6>;
			atmel,nand-addr-offset = <21>;
			atmel,nand-cmd-offset = <22>;
			atmel,nand-has-dma;
			atmel,nand-pmecc-correct-erase-page;
			pinctrl-names = "default";
			pinctrl-0 = <&pinctrl_nand>;
			status = "disabled";

			nfc@90000000 {
				compatible = "atmel,sama5d3-nfc";
				#address-cells = <1>;
				#size-cells = <1>;
				reg = <
					0x90000000 0x08000000	/* NFC Command Registers */
					0x98000000 0x4		/* NFC busy Registers */
					0xfc05c000 0x00000070	/* NFC HSMC regs */
					0x00100000 0x00100000	/* NFC SRAM banks */
                                         >;
				atmel,write-by-sram;
			};
		};
	};
};
